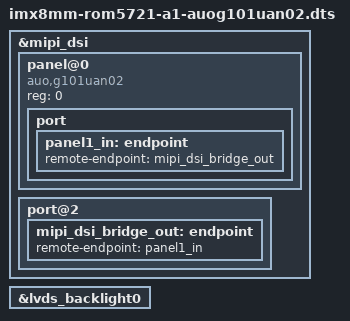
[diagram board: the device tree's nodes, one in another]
/*
 * Copyright 2018 NXP
 *
 * This program is free software; you can redistribute it and/or
 * modify it under the terms of the GNU General Public License
 * as published by the Free Software Foundation; either version 2
 * of the License, or (at your option) any later version.
 *
 * This program is distributed in the hope that it will be useful,
 * but WITHOUT ANY WARRANTY; without even the implied warranty of
 * MERCHANTABILITY or FITNESS FOR A PARTICULAR PURPOSE.  See the
 * GNU General Public License for more details.
 */

#include "imx8mm-rom5721-a1.dts"


&mipi_dsi {
        panel@0 {
                compatible = "auo,g101uan02";
                reg = <0>;
                port {
                        panel1_in: endpoint {
                                remote-endpoint = <&mipi_dsi_bridge_out>;
                        };
                };
        };
        port@2 {
                mipi_dsi_bridge_out: endpoint {
                        remote-endpoint = <&panel1_in>;
                };
        };
};
&lvds_backlight0 {
	/delete-property/lvds-reset;
	/delete-property/lvds-stby;
	/delete-property/lvds-bkl-delay-time;
        status = "okay";
};

